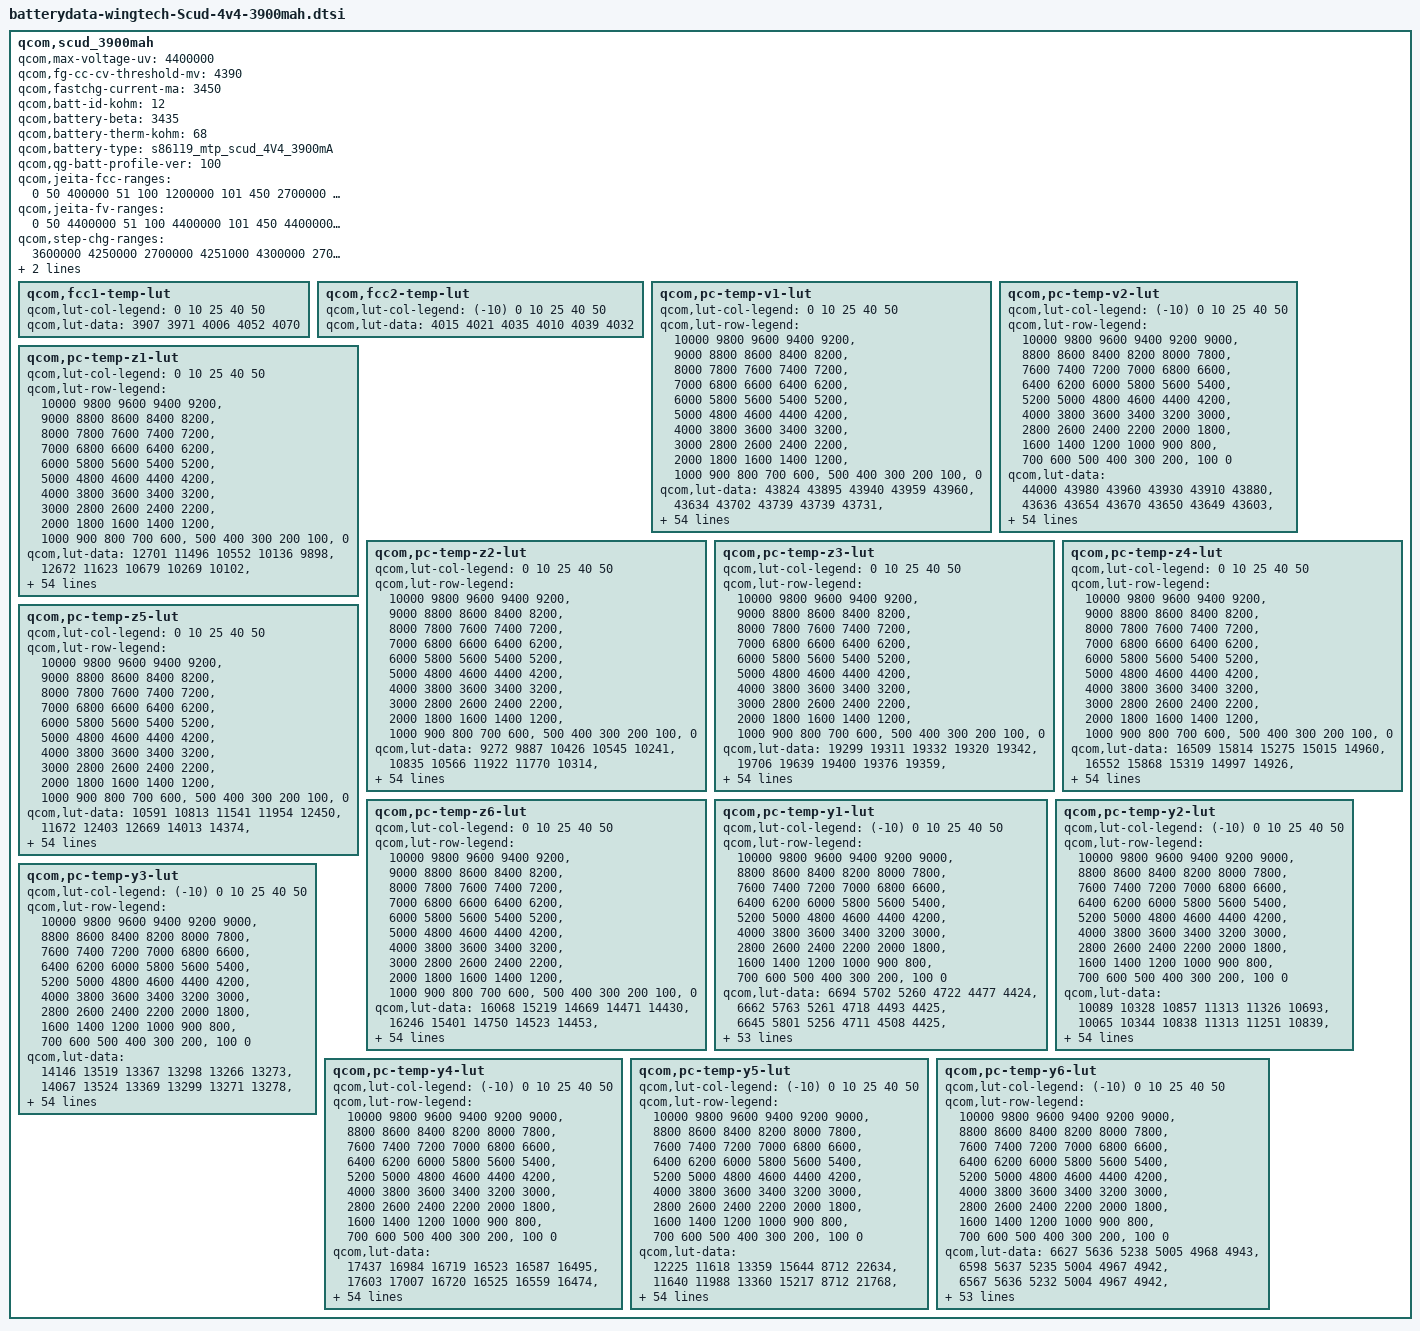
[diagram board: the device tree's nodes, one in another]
/* Copyright (c) 2018, The Linux Foundation. All rights reserved.
 *
 * This program is free software; you can redistribute it and/or modify
 * it under the terms of the GNU General Public License version 2 and
 * only version 2 as published by the Free Software Foundation.
 *
 * This program is distributed in the hope that it will be useful,
 * but WITHOUT ANY WARRANTY; without even the implied warranty of
 * MERCHANTABILITY or FITNESS FOR A PARTICULAR PURPOSE.  See the
 * GNU General Public License for more details.
 */

qcom,scud_3900mah {
	/* Scud_wConn_3900mAh_Fresh_averaged_MasterSlave_Feb7th2018 */
	qcom,max-voltage-uv = <4400000>;
	qcom,fg-cc-cv-threshold-mv = <4390>;
	qcom,fastchg-current-ma = <3450>;
	qcom,batt-id-kohm = <12>;
	qcom,battery-beta = <3435>;
	qcom,battery-therm-kohm = <68>;
	qcom,battery-type =
		"s86119_mtp_scud_4V4_3900mA";
	qcom,qg-batt-profile-ver = <100>;
	//+Bug 439935 gudi.wt,MODIFIY,20190628,S86119AA1 set follow to batt spec
	qcom,jeita-fcc-ranges = <0   50  400000
				51  100  1200000
				101  450 2700000
				451  600 1400000>;
	qcom,jeita-fv-ranges = <0   50  4400000
				51 100  4400000
				101 450 4400000
				451 600  4100000>;
	qcom,step-chg-ranges = <3600000  4250000  2700000
				4251000  4300000  2700000
				4301000  4400000  2700000>;

	/* COOL = 5 DegC, WARM = 45 DegC */
	qcom,jeita-soft-thresholds = <0x2E1E 0x123E>;
	/* COLD = 0 DegC, HOT = 55 DegC */
	qcom,jeita-hard-thresholds = <0x3480 0x0F3B>;
	//+Bug 439935 gudi.wt,MODIFIY,20190628,S86119AA1 set follow to batt spec
	qcom,fcc1-temp-lut {
		qcom,lut-col-legend = <0 10 25 40 50>;
		qcom,lut-data = <3907 3971 4006 4052 4070>;
	};

	qcom,fcc2-temp-lut {
		qcom,lut-col-legend = <(-10) 0 10 25 40 50>;
		qcom,lut-data = <4015 4021 4035 4010 4039 4032>;
	};

	qcom,pc-temp-v1-lut {
		qcom,lut-col-legend = <0 10 25 40 50>;
		qcom,lut-row-legend = <10000 9800 9600 9400 9200>,
			<9000 8800 8600 8400 8200>,
			<8000 7800 7600 7400 7200>,
			<7000 6800 6600 6400 6200>,
			<6000 5800 5600 5400 5200>,
			<5000 4800 4600 4400 4200>,
			<4000 3800 3600 3400 3200>,
			<3000 2800 2600 2400 2200>,
			<2000 1800 1600 1400 1200>,
			<1000 900 800 700 600>,
			<500 400 300 200 100>,
			<0>;
		qcom,lut-data = <43824 43895 43940 43959 43960>,
			<43634 43702 43739 43739 43731>,
			<43361 43461 43491 43522 43507>,
			<43106 43204 43258 43293 43285>,
			<42867 42961 43027 43060 43062>,
			<42631 42724 42792 42826 42834>,
			<42399 42491 42558 42593 42600>,
			<42171 42260 42324 42359 42365>,
			<41947 42034 42091 42128 42133>,
			<41728 41811 41862 41898 41903>,
			<41516 41589 41637 41670 41674>,
			<41321 41378 41418 41445 41449>,
			<41134 41183 41206 41227 41230>,
			<40931 40987 41003 41016 41018>,
			<40705 40771 40795 40809 40811>,
			<40477 40545 40585 40604 40606>,
			<40248 40335 40383 40405 40407>,
			<40026 40136 40191 40218 40220>,
			<39854 39957 40010 40040 40044>,
			<39720 39807 39846 39869 39872>,
			<39598 39672 39700 39716 39713>,
			<39473 39528 39536 39549 39545>,
			<39351 39382 39333 39309 39320>,
			<39232 39221 39120 39033 39048>,
			<39115 39017 38917 38851 38859>,
			<38999 38806 38720 38732 38742>,
			<38876 38659 38586 38631 38643>,
			<38755 38547 38500 38539 38545>,
			<38648 38463 38429 38456 38454>,
			<38551 38402 38364 38375 38365>,
			<38470 38353 38305 38298 38280>,
			<38405 38310 38248 38226 38203>,
			<38351 38273 38195 38162 38134>,
			<38307 38236 38143 38100 38070>,
			<38274 38199 38095 38041 38009>,
			<38239 38160 38049 37984 37950>,
			<38201 38120 38003 37930 37887>,
			<38159 38078 37960 37883 37823>,
			<38104 38021 37902 37824 37750>,
			<38030 37932 37811 37734 37660>,
			<37938 37822 37698 37621 37554>,
			<37811 37697 37578 37499 37433>,
			<37658 37553 37444 37361 37290>,
			<37487 37393 37286 37204 37137>,
			<37350 37253 37148 37063 37003>,
			<37253 37163 37067 36989 36925>,
			<37216 37137 37044 36968 36905>,
			<37190 37115 37030 36953 36891>,
			<37163 37098 37008 36932 36866>,
			<37107 37032 36926 36841 36757>,
			<36855 36755 36634 36540 36447>,
			<36406 36307 36180 36084 35990>,
			<35820 35712 35588 35491 35397>,
			<35020 34897 34775 34676 34583>,
			<33768 33616 33496 33401 33311>,
			<30000 30000 30000 30000 30000>;
	};

	qcom,pc-temp-v2-lut {
		qcom,lut-col-legend = <(-10) 0 10 25 40 50>;
		qcom,lut-row-legend = <10000 9800 9600 9400 9200 9000>,
			<8800 8600 8400 8200 8000 7800>,
			<7600 7400 7200 7000 6800 6600>,
			<6400 6200 6000 5800 5600 5400>,
			<5200 5000 4800 4600 4400 4200>,
			<4000 3800 3600 3400 3200 3000>,
			<2800 2600 2400 2200 2000 1800>,
			<1600 1400 1200 1000 900 800>,
			<700 600 500 400 300 200>,
			<100 0>;
		qcom,lut-data = <44000 43980 43960 43930 43910 43880>,
			<43636 43654 43670 43650 43649 43603>,
			<43299 43351 43397 43385 43395 43340>,
			<42990 43075 43138 43134 43149 43093>,
			<42705 42824 42895 42898 42909 42861>,
			<42446 42579 42657 42665 42672 42633>,
			<42224 42333 42422 42430 42435 42405>,
			<42006 42095 42191 42197 42203 42178>,
			<41733 41871 41962 41967 41981 41947>,
			<41426 41657 41735 41740 41766 41714>,
			<41217 41441 41512 41516 41546 41489>,
			<41108 41220 41293 41293 41321 41273>,
			<40990 41010 41083 41076 41099 41061>,
			<40758 40835 40898 40876 40890 40850>,
			<40433 40670 40718 40682 40686 40640>,
			<40115 40435 40503 40479 40482 40438>,
			<39784 40087 40245 40260 40277 40240>,
			<39512 39781 39994 40058 40085 40054>,
			<39337 39585 39766 39892 39917 39888>,
			<39192 39418 39551 39736 39751 39724>,
			<39034 39247 39357 39542 39560 39537>,
			<38870 39078 39178 39310 39350 39332>,
			<38714 38917 39011 39094 39145 39130>,
			<38556 38761 38850 38906 38939 38926>,
			<38416 38617 38703 38739 38758 38744>,
			<38309 38491 38573 38604 38623 38608>,
			<38222 38378 38455 38490 38512 38496>,
			<38147 38262 38346 38385 38406 38391>,
			<38080 38136 38246 38289 38307 38294>,
			<38018 38032 38152 38199 38216 38204>,
			<37954 37966 38063 38118 38139 38124>,
			<37891 37915 37981 38043 38067 38050>,
			<37830 37868 37907 37974 37994 37980>,
			<37769 37826 37838 37912 37921 37917>,
			<37710 37783 37782 37851 37845 37843>,
			<37653 37737 37743 37785 37763 37742>,
			<37597 37688 37706 37717 37677 37631>,
			<37536 37632 37663 37645 37583 37526>,
			<37470 37567 37614 37568 37485 37423>,
			<37406 37494 37550 37488 37397 37330>,
			<37346 37410 37462 37408 37325 37252>,
			<37285 37312 37358 37316 37231 37158>,
			<37216 37197 37235 37197 37106 37036>,
			<37139 37092 37086 37051 36970 36898>,
			<37046 36986 36960 36925 36852 36788>,
			<36934 36899 36901 36886 36823 36764>,
			<36865 36863 36880 36872 36808 36748>,
			<36795 36828 36856 36853 36788 36725>,
			<36684 36771 36816 36811 36741 36676>,
			<36534 36652 36706 36695 36609 36512>,
			<36274 36398 36404 36367 36243 36122>,
			<35851 35949 35893 35864 35723 35595>,
			<35236 35323 35219 35206 35044 34905>,
			<34338 34435 34268 34298 34098 33972>,
			<32794 33041 32942 33023 32903 32631>,
			<28257 29235 28091 28288 28281 28415>;
	};

	qcom,pc-temp-z1-lut {
		qcom,lut-col-legend = <0 10 25 40 50>;
		qcom,lut-row-legend = <10000 9800 9600 9400 9200>,
			<9000 8800 8600 8400 8200>,
			<8000 7800 7600 7400 7200>,
			<7000 6800 6600 6400 6200>,
			<6000 5800 5600 5400 5200>,
			<5000 4800 4600 4400 4200>,
			<4000 3800 3600 3400 3200>,
			<3000 2800 2600 2400 2200>,
			<2000 1800 1600 1400 1200>,
			<1000 900 800 700 600>,
			<500 400 300 200 100>,
			<0>;
		qcom,lut-data = <12701 11496 10552 10136 9898>,
			<12672 11623 10679 10269 10102>,
			<12762 11650 10684 10271 10108>,
			<12801 11686 10672 10270 10105>,
			<12815 11691 10661 10270 10102>,
			<12820 11689 10653 10266 10099>,
			<12807 11685 10645 10257 10097>,
			<12783 11665 10641 10252 10095>,
			<12773 11640 10637 10250 10093>,
			<12788 11630 10634 10249 10092>,
			<12801 11627 10631 10248 10091>,
			<12796 11620 10627 10247 10089>,
			<12788 11609 10625 10247 10089>,
			<12767 11594 10622 10245 10089>,
			<12693 11576 10619 10243 10089>,
			<12634 11555 10614 10241 10088>,
			<12628 11544 10612 10239 10088>,
			<12624 11545 10614 10238 10088>,
			<12625 11548 10617 10237 10089>,
			<12637 11552 10617 10237 10089>,
			<12646 11558 10615 10240 10089>,
			<12636 11559 10615 10242 10089>,
			<12611 11559 10619 10243 10089>,
			<12585 11561 10625 10244 10090>,
			<12550 11568 10628 10245 10091>,
			<12530 11578 10631 10247 10095>,
			<12561 11581 10634 10249 10098>,
			<12618 11582 10640 10252 10101>,
			<12627 11584 10647 10256 10104>,
			<12598 11588 10652 10258 10107>,
			<12574 11591 10657 10260 10108>,
			<12573 11588 10659 10263 10110>,
			<12577 11579 10661 10268 10114>,
			<12588 11575 10662 10274 10120>,
			<12609 11575 10667 10278 10123>,
			<12626 11576 10674 10281 10127>,
			<12636 11579 10680 10282 10129>,
			<12644 11583 10686 10283 10129>,
			<12651 11588 10692 10284 10130>,
			<12660 11600 10700 10287 10133>,
			<12665 11615 10707 10292 10137>,
			<12658 11632 10714 10295 10138>,
			<12642 11647 10722 10298 10139>,
			<12605 11636 10723 10301 10141>,
			<12581 11631 10728 10306 10144>,
			<12558 11619 10731 10310 10148>,
			<12626 11630 10736 10312 10149>,
			<12582 11588 10732 10315 10147>,
			<12565 11605 10731 10313 10149>,
			<12599 11606 10736 10317 10150>,
			<12619 11655 10740 10325 10155>,
			<12546 11672 10750 10325 10159>,
			<12580 11632 10768 10332 10169>,
			<12606 11680 10789 10343 10175>,
			<12606 11680 10789 10343 10175>,
			<12606 11680 10789 10343 10175>;
	};

	qcom,pc-temp-z2-lut {
		qcom,lut-col-legend = <0 10 25 40 50>;
		qcom,lut-row-legend = <10000 9800 9600 9400 9200>,
			<9000 8800 8600 8400 8200>,
			<8000 7800 7600 7400 7200>,
			<7000 6800 6600 6400 6200>,
			<6000 5800 5600 5400 5200>,
			<5000 4800 4600 4400 4200>,
			<4000 3800 3600 3400 3200>,
			<3000 2800 2600 2400 2200>,
			<2000 1800 1600 1400 1200>,
			<1000 900 800 700 600>,
			<500 400 300 200 100>,
			<0>;
		qcom,lut-data = <9272 9887 10426 10545 10241>,
			<10835 10566 11922 11770 10314>,
			<10312 10422 10557 11544 10575>,
			<10154 10226 10509 11106 10574>,
			<10144 10188 10469 10572 10504>,
			<10140 10180 10427 10500 10480>,
			<10151 10181 10399 10475 10474>,
			<10171 10188 10422 10468 10472>,
			<10176 10197 10481 10485 10477>,
			<10172 10204 10502 10508 10485>,
			<10169 10210 10494 10612 10489>,
			<10177 10216 10486 10793 10497>,
			<10192 10231 10486 10864 10484>,
			<10195 10245 10494 10895 10354>,
			<10190 10243 10523 10907 10245>,
			<10182 10229 10622 10873 10257>,
			<10164 10233 10685 10818 10287>,
			<10141 10276 10626 10735 10302>,
			<10142 10310 10536 10557 10308>,
			<10194 10306 10519 10493 10315>,
			<10244 10298 10532 10498 10332>,
			<10267 10296 10556 10514 10363>,
			<10284 10299 10627 10592 10487>,
			<10286 10304 10692 10720 10752>,
			<10274 10318 10686 10731 10819>,
			<10260 10336 10653 10609 10595>,
			<10246 10343 10629 10526 10415>,
			<10233 10347 10610 10560 10434>,
			<10231 10349 10599 10618 10487>,
			<10236 10350 10617 10657 10581>,
			<10244 10351 10656 10738 10784>,
			<10252 10354 10674 10769 10876>,
			<10261 10362 10689 10712 10742>,
			<10271 10369 10695 10655 10571>,
			<10280 10373 10673 10646 10505>,
			<10291 10377 10643 10644 10458>,
			<10303 10383 10639 10655 10474>,
			<10317 10392 10647 10710 10681>,
			<10340 10402 10659 10775 10835>,
			<10383 10415 10691 10848 10808>,
			<10427 10429 10728 10910 10765>,
			<10454 10443 10746 10896 10765>,
			<10488 10465 10763 10836 10795>,
			<10609 10520 10794 10841 10775>,
			<10542 10728 10887 10857 10689>,
			<10369 11076 11026 10767 10535>,
			<10368 11114 10971 10647 10510>,
			<10383 11244 11064 10617 10534>,
			<10300 11276 11008 10666 10575>,
			<10198 11123 11119 10780 10720>,
			<10328 11394 11357 10757 10510>,
			<10272 10919 11348 10793 10383>,
			<10040 10881 11178 10737 10259>,
			<9881 10675 11091 10551 10200>,
			<9881 10675 11091 10551 10200>,
			<9881 10675 11091 10551 10200>;
	};

	qcom,pc-temp-z3-lut {
		qcom,lut-col-legend = <0 10 25 40 50>;
		qcom,lut-row-legend = <10000 9800 9600 9400 9200>,
			<9000 8800 8600 8400 8200>,
			<8000 7800 7600 7400 7200>,
			<7000 6800 6600 6400 6200>,
			<6000 5800 5600 5400 5200>,
			<5000 4800 4600 4400 4200>,
			<4000 3800 3600 3400 3200>,
			<3000 2800 2600 2400 2200>,
			<2000 1800 1600 1400 1200>,
			<1000 900 800 700 600>,
			<500 400 300 200 100>,
			<0>;
		qcom,lut-data = <19299 19311 19332 19320 19342>,
			<19706 19639 19400 19376 19359>,
			<19945 19748 19549 19438 19425>,
			<20037 19820 19593 19478 19451>,
			<20073 19850 19605 19501 19460>,
			<20089 19868 19604 19501 19460>,
			<20068 19873 19601 19496 19454>,
			<20025 19861 19594 19490 19448>,
			<20010 19844 19581 19474 19439>,
			<20013 19835 19566 19459 19430>,
			<20014 19826 19547 19460 19426>,
			<19999 19815 19531 19467 19420>,
			<19978 19798 19520 19466 19411>,
			<19975 19783 19511 19460 19388>,
			<19997 19784 19509 19453 19372>,
			<20029 19791 19520 19443 19371>,
			<20078 19786 19530 19430 19372>,
			<20132 19740 19531 19416 19370>,
			<20133 19702 19532 19396 19363>,
			<20057 19699 19523 19386 19358>,
			<19996 19699 19489 19380 19356>,
			<19989 19703 19472 19377 19353>,
			<19991 19714 19489 19390 19360>,
			<19998 19728 19509 19418 19378>,
			<20012 19752 19512 19422 19383>,
			<20030 19778 19510 19404 19364>,
			<20055 19781 19504 19387 19345>,
			<20082 19776 19493 19375 19339>,
			<20088 19770 19480 19367 19335>,
			<20084 19763 19469 19369 19341>,
			<20079 19754 19459 19382 19370>,
			<20070 19742 19459 19393 19387>,
			<20057 19728 19468 19406 19389>,
			<20042 19718 19477 19415 19388>,
			<20013 19713 19482 19414 19382>,
			<19980 19708 19486 19410 19370>,
			<19951 19704 19486 19405 19367>,
			<19921 19700 19482 19399 19370>,
			<19888 19696 19477 19394 19372>,
			<19850 19689 19471 19390 19367>,
			<19814 19680 19464 19387 19360>,
			<19787 19671 19460 19385 19361>,
			<19757 19656 19456 19385 19369>,
			<19717 19626 19450 19384 19366>,
			<19518 19549 19430 19381 19353>,
			<19348 19454 19397 19352 19337>,
			<19345 19438 19395 19348 19333>,
			<19339 19409 19377 19344 19328>,
			<19332 19329 19375 19332 19320>,
			<19327 19366 19349 19324 19319>,
			<19340 19383 19324 19319 19328>,
			<19348 19338 19321 19315 19331>,
			<19347 19338 19315 19321 19338>,
			<19357 19333 19305 19322 19339>,
			<19357 19333 19305 19322 19339>,
			<19357 19333 19305 19322 19339>;
	};

	qcom,pc-temp-z4-lut {
		qcom,lut-col-legend = <0 10 25 40 50>;
		qcom,lut-row-legend = <10000 9800 9600 9400 9200>,
			<9000 8800 8600 8400 8200>,
			<8000 7800 7600 7400 7200>,
			<7000 6800 6600 6400 6200>,
			<6000 5800 5600 5400 5200>,
			<5000 4800 4600 4400 4200>,
			<4000 3800 3600 3400 3200>,
			<3000 2800 2600 2400 2200>,
			<2000 1800 1600 1400 1200>,
			<1000 900 800 700 600>,
			<500 400 300 200 100>,
			<0>;
		qcom,lut-data = <16509 15814 15275 15015 14960>,
			<16552 15868 15319 14997 14926>,
			<16740 15830 15397 15083 14955>,
			<16771 15761 15270 15038 14956>,
			<16575 15667 15166 14964 14898>,
			<16338 15505 15106 14910 14854>,
			<16172 15373 15053 14862 14816>,
			<16023 15291 14988 14839 14796>,
			<15899 15223 14923 14830 14789>,
			<15795 15162 14897 14822 14784>,
			<15706 15108 14889 14801 14777>,
			<15630 15057 14882 14770 14766>,
			<15563 15005 14869 14751 14763>,
			<15498 14961 14851 14737 14767>,
			<15430 14925 14834 14728 14771>,
			<15366 14894 14804 14725 14762>,
			<15303 14890 14774 14723 14743>,
			<15248 14923 14749 14722 14729>,
			<15236 14951 14726 14726 14718>,
			<15259 14930 14720 14727 14712>,
			<15273 14881 14730 14725 14710>,
			<15231 14846 14746 14725 14709>,
			<15146 14818 14765 14756 14734>,
			<15080 14805 14787 14825 14807>,
			<15024 14829 14827 14859 14847>,
			<14981 14871 14886 14877 14865>,
			<14948 14892 14904 14884 14873>,
			<14920 14907 14901 14881 14869>,
			<14911 14913 14896 14873 14859>,
			<14910 14906 14889 14857 14837>,
			<14909 14893 14877 14825 14787>,
			<14907 14882 14859 14793 14748>,
			<14904 14870 14829 14757 14724>,
			<14901 14857 14800 14731 14710>,
			<14899 14843 14776 14725 14710>,
			<14898 14829 14756 14722 14712>,
			<14901 14817 14748 14722 14715>,
			<14905 14804 14743 14724 14717>,
			<14909 14800 14742 14729 14721>,
			<14917 14800 14758 14742 14732>,
			<14922 14800 14776 14758 14747>,
			<14922 14798 14774 14758 14746>,
			<14922 14793 14766 14750 14733>,
			<14903 14794 14762 14746 14735>,
			<14957 14789 14752 14738 14738>,
			<15029 14789 14720 14715 14709>,
			<15031 14799 14709 14706 14698>,
			<15029 14823 14709 14686 14678>,
			<15031 14903 14697 14681 14664>,
			<15023 14857 14732 14699 14679>,
			<15021 14855 14793 14741 14703>,
			<15028 14920 14807 14752 14706>,
			<15045 14927 14820 14747 14701>,
			<15051 14943 14835 14749 14701>,
			<15051 14943 14835 14749 14701>,
			<15051 14943 14835 14749 14701>;
	};

	qcom,pc-temp-z5-lut {
		qcom,lut-col-legend = <0 10 25 40 50>;
		qcom,lut-row-legend = <10000 9800 9600 9400 9200>,
			<9000 8800 8600 8400 8200>,
			<8000 7800 7600 7400 7200>,
			<7000 6800 6600 6400 6200>,
			<6000 5800 5600 5400 5200>,
			<5000 4800 4600 4400 4200>,
			<4000 3800 3600 3400 3200>,
			<3000 2800 2600 2400 2200>,
			<2000 1800 1600 1400 1200>,
			<1000 900 800 700 600>,
			<500 400 300 200 100>,
			<0>;
		qcom,lut-data = <10591 10813 11541 11954 12450>,
			<11672 12403 12669 14013 14374>,
			<12465 13253 14746 14821 16533>,
			<12835 13841 15318 15727 16919>,
			<13006 14292 15539 16708 17258>,
			<13133 14664 15582 17319 17707>,
			<13257 14884 15619 17854 18508>,
			<13374 15023 16106 17993 19029>,
			<13512 15174 17031 17691 18821>,
			<13696 15401 17271 17422 18463>,
			<13857 15810 16987 18278 18495>,
			<13912 16290 16762 20191 18571>,
			<13917 16856 16912 21564 18285>,
			<14017 17581 17181 22720 16967>,
			<14337 18999 17476 23205 15951>,
			<14819 20986 19439 22738 16369>,
			<15888 21302 21654 21904 17287>,
			<17249 18700 23830 20839 17814>,
			<17369 16549 25957 19143 18301>,
			<16032 16933 26120 18758 18643>,
			<15034 18157 23843 19196 19102>,
			<15387 19892 23488 19984 20002>,
			<16322 23137 32117 25736 23536>,
			<17503 27594 41970 36239 30940>,
			<19296 36618 43062 37572 32778>,
			<21651 46677 40353 29543 25823>,
			<25653 47664 36928 22563 19130>,
			<30521 43843 31739 19505 17022>,
			<33033 39772 26828 17542 15743>,
			<34691 36390 23604 17232 15934>,
			<35761 33169 21154 17605 17830>,
			<35442 30428 20700 18335 19786>,
			<34063 27892 21363 20620 21851>,
			<32611 26868 22314 23545 23590>,
			<29713 26742 24216 26229 24168>,
			<26874 26674 26668 28718 24538>,
			<24984 26932 28084 29179 25208>,
			<23328 27728 29139 28514 27163>,
			<21956 28065 29473 27482 28479>,
			<20574 28669 28087 25117 25377>,
			<19667 29143 26060 22279 20440>,
			<19337 28591 24792 21270 19931>,
			<19127 27368 23840 20799 20809>,
			<19413 25148 22870 20398 19907>,
			<16442 22199 22233 20178 18005>,
			<12973 18593 21230 18713 17447>,
			<12872 16843 20911 18148 17294>,
			<12719 15247 18407 18384 17682>,
			<12590 12790 18434 17667 18456>,
			<12618 14171 16119 15930 17259>,
			<12913 14437 13665 13726 14818>,
			<12877 12937 13151 13132 14416>,
			<12662 12805 12759 13181 14552>,
			<12541 12512 12349 13008 14368>,
			<12541 12512 12349 13008 14368>,
			<12541 12512 12349 13008 14368>;
	};

	qcom,pc-temp-z6-lut {
		qcom,lut-col-legend = <0 10 25 40 50>;
		qcom,lut-row-legend = <10000 9800 9600 9400 9200>,
			<9000 8800 8600 8400 8200>,
			<8000 7800 7600 7400 7200>,
			<7000 6800 6600 6400 6200>,
			<6000 5800 5600 5400 5200>,
			<5000 4800 4600 4400 4200>,
			<4000 3800 3600 3400 3200>,
			<3000 2800 2600 2400 2200>,
			<2000 1800 1600 1400 1200>,
			<1000 900 800 700 600>,
			<500 400 300 200 100>,
			<0>;
		qcom,lut-data = <16068 15219 14669 14471 14430>,
			<16246 15401 14750 14523 14453>,
			<16391 15412 14840 14592 14503>,
			<16416 15417 14813 14585 14514>,
			<16340 15400 14784 14572 14498>,
			<16237 15325 14758 14556 14481>,
			<16133 15256 14730 14531 14463>,
			<16021 15207 14697 14513 14449>,
			<15945 15163 14662 14500 14441>,
			<15895 15126 14640 14489 14434>,
			<15851 15093 14627 14479 14427>,
			<15800 15061 14616 14471 14420>,
			<15750 15027 14604 14462 14412>,
			<15709 14997 14591 14453 14403>,
			<15670 14977 14582 14444 14395>,
			<15645 14962 14574 14436 14388>,
			<15641 14951 14566 14428 14381>,
			<15643 14944 14557 14419 14374>,
			<15635 14936 14546 14410 14365>,
			<15614 14921 14536 14404 14359>,
			<15587 14904 14525 14400 14356>,
			<15552 14897 14521 14398 14354>,
			<15511 14894 14537 14420 14370>,
			<15486 14893 14560 14465 14413>,
			<15468 14915 14580 14476 14428>,
			<15460 14951 14604 14475 14425>,
			<15466 14960 14610 14473 14421>,
			<15476 14962 14604 14467 14417>,
			<15477 14962 14595 14459 14411>,
			<15468 14958 14587 14453 14405>,
			<15460 14950 14578 14446 14399>,
			<15461 14940 14570 14439 14393>,
			<15463 14926 14562 14432 14386>,
			<15457 14915 14555 14426 14379>,
			<15441 14908 14549 14422 14375>,
			<15426 14902 14543 14419 14371>,
			<15415 14897 14540 14417 14370>,
			<15405 14892 14536 14415 14372>,
			<15392 14890 14535 14414 14374>,
			<15373 14891 14540 14418 14377>,
			<15359 14892 14546 14423 14379>,
			<15355 14890 14545 14423 14379>,
			<15349 14886 14540 14419 14378>,
			<15319 14870 14535 14418 14377>,
			<15231 14827 14522 14413 14373>,
			<15168 14787 14493 14389 14352>,
			<15182 14786 14487 14382 14346>,
			<15173 14775 14478 14373 14333>,
			<15166 14769 14471 14363 14323>,
			<15175 14776 14474 14368 14328>,
			<15191 14788 14489 14385 14346>,
			<15191 14804 14495 14389 14351>,
			<15210 14805 14502 14392 14355>,
			<15249 14826 14509 14396 14358>,
			<15249 14826 14509 14396 14358>,
			<15249 14826 14509 14396 14358>;
	};

	qcom,pc-temp-y1-lut {
		qcom,lut-col-legend = <(-10) 0 10 25 40 50>;
		qcom,lut-row-legend = <10000 9800 9600 9400 9200 9000>,
			<8800 8600 8400 8200 8000 7800>,
			<7600 7400 7200 7000 6800 6600>,
			<6400 6200 6000 5800 5600 5400>,
			<5200 5000 4800 4600 4400 4200>,
			<4000 3800 3600 3400 3200 3000>,
			<2800 2600 2400 2200 2000 1800>,
			<1600 1400 1200 1000 900 800>,
			<700 600 500 400 300 200>,
			<100 0>;
		qcom,lut-data = <6694 5702 5260 4722 4477 4424>,
			<6662 5763 5261 4718 4493 4425>,
			<6645 5801 5256 4711 4508 4425>,
			<6640 5822 5250 4703 4522 4424>,
			<6640 5830 5245 4696 4535 4422>,
			<6641 5831 5243 4692 4544 4419>,
			<6653 5802 5242 4688 4554 4401>,
			<6666 5770 5241 4685 4560 4383>,
			<6661 5774 5240 4683 4554 4388>,
			<6645 5790 5239 4681 4541 4406>,
			<6639 5795 5237 4678 4537 4409>,
			<6631 5789 5230 4674 4538 4390>,
			<6628 5783 5221 4671 4539 4373>,
			<6643 5784 5209 4669 4514 4369>,
			<6665 5787 5197 4669 4473 4367>,
			<6676 5788 5195 4668 4466 4369>,
			<6688 5789 5199 4667 4473 4377>,
			<6695 5791 5201 4666 4476 4382>,
			<6669 5801 5202 4667 4472 4381>,
			<6631 5815 5203 4669 4467 4379>,
			<6632 5819 5203 4670 4481 4376>,
			<6653 5824 5202 4671 4523 4368>,
			<6664 5827 5203 4673 4537 4366>,
			<6663 5819 5207 4676 4532 4375>,
			<6661 5810 5211 4680 4522 4383>,
			<6657 5811 5211 4682 4498 4380>,
			<6648 5811 5207 4684 4467 4372>,
			<6645 5810 5207 4687 4463 4371>,
			<6653 5805 5210 4691 4475 4373>,
			<6657 5800 5213 4696 4492 4376>,
			<6635 5796 5218 4702 4521 4377>,
			<6599 5788 5225 4709 4548 4378>,
			<6592 5781 5225 4711 4538 4380>,
			<6607 5774 5223 4711 4492 4383>,
			<6619 5771 5226 4712 4474 4386>,
			<6632 5788 5241 4717 4477 4390>,
			<6647 5808 5255 4726 4480 4394>,
			<6647 5803 5251 4732 4483 4394>,
			<6639 5780 5241 4737 4487 4394>,
			<6628 5772 5239 4740 4489 4395>,
			<6611 5778 5257 4739 4491 4398>,
			<6601 5781 5259 4740 4491 4400>,
			<6610 5779 5244 4746 4492 4399>,
			<6579 5812 5267 4747 4499 4401>,
			<6623 5824 5277 4754 4499 4404>,
			<6644 5812 5272 4754 4506 4404>,
			<6629 5795 5272 4758 4504 4406>,
			<6637 5787 5257 4762 4504 4402>,
			<6616 5768 5280 4765 4499 4405>,
			<6604 5788 5276 4765 4502 4402>,
			<6616 5825 5281 4767 4500 4405>,
			<6581 5801 5291 4773 4508 4409>,
			<6693 5792 5305 4781 4514 4415>,
			<6733 5855 5300 4796 4525 4421>,
			<6733 5855 5300 4796 4525 4421>,
			<6733 5855 5300 4796 4525 4421>;
	};

	qcom,pc-temp-y2-lut {
		qcom,lut-col-legend = <(-10) 0 10 25 40 50>;
		qcom,lut-row-legend = <10000 9800 9600 9400 9200 9000>,
			<8800 8600 8400 8200 8000 7800>,
			<7600 7400 7200 7000 6800 6600>,
			<6400 6200 6000 5800 5600 5400>,
			<5200 5000 4800 4600 4400 4200>,
			<4000 3800 3600 3400 3200 3000>,
			<2800 2600 2400 2200 2000 1800>,
			<1600 1400 1200 1000 900 800>,
			<700 600 500 400 300 200>,
			<100 0>;
		qcom,lut-data = <10089 10328 10857 11313 11326 10693>,
			<10065 10344 10838 11313 11251 10839>,
			<10058 10360 10816 11306 11175 10946>,
			<10066 10376 10796 11294 11108 11017>,
			<10084 10392 10780 11278 11062 11053>,
			<10108 10408 10773 11258 11049 11055>,
			<10139 10427 10771 11228 11068 11006>,
			<10184 10442 10771 11201 11089 10946>,
			<10295 10434 10780 11195 11039 10917>,
			<10483 10411 10797 11205 10912 10897>,
			<10542 10408 10804 11222 10886 10897>,
			<10485 10473 10804 11266 11012 10957>,
			<10435 10558 10804 11301 11131 11031>,
			<10491 10637 10810 11295 11173 11087>,
			<10605 10709 10823 11275 11207 11139>,
			<10556 10721 10851 11281 11223 11183>,
			<10052 10711 10919 11351 11245 11219>,
			<9703 10705 10957 11406 11274 11263>,
			<9686 10741 10954 11414 11334 11347>,
			<9677 10806 10950 11414 11389 11426>,
			<9673 10858 10961 11397 11388 11444>,
			<9671 10908 10997 11347 11365 11451>,
			<9669 10961 11036 11321 11329 11442>,
			<9668 11037 11079 11330 11230 11251>,
			<9666 11092 11121 11348 11155 11073>,
			<9665 11080 11156 11376 11224 11107>,
			<9663 11044 11188 11418 11364 11199>,
			<9662 11043 11210 11449 11409 11237>,
			<9661 11136 11229 11473 11410 11247>,
			<9661 11211 11237 11492 11409 11258>,
			<9660 11184 11225 11500 11385 11319>,
			<9660 11120 11209 11502 11357 11409>,
			<9659 11066 11210 11501 11399 11459>,
			<9658 11018 11227 11498 11508 11539>,
			<9658 10951 11235 11494 11548 11572>,
			<9658 10666 11211 11487 11440 11557>,
			<9657 10343 11175 11478 11323 11527>,
			<9657 10179 11129 11474 11302 11452>,
			<9657 9845 11067 11472 11303 11302>,
			<9657 9683 11035 11468 11289 11189>,
			<9656 9674 11019 11448 11180 11100>,
			<9656 9669 10988 11433 11143 11100>,
			<9656 9666 10926 11442 11153 11185>,
			<9656 9663 10892 11345 11310 11094>,
			<9656 9665 10864 11360 11051 11162>,
			<9656 9662 10815 11312 11129 11028>,
			<9656 9660 10755 11310 11249 10904>,
			<9655 9659 10692 11221 11112 10796>,
			<9655 9658 10637 11180 11032 10934>,
			<9655 9657 10441 11166 11118 10792>,
			<9654 9656 10611 11218 11017 10820>,
			<9654 9655 10500 11152 10861 10684>,
			<9653 9654 10384 10973 10834 10665>,
			<9651 9653 10078 10883 10844 10683>,
			<9651 9653 10078 10883 10844 10683>,
			<9651 9653 10078 10883 10844 10683>;
	};

	qcom,pc-temp-y3-lut {
		qcom,lut-col-legend = <(-10) 0 10 25 40 50>;
		qcom,lut-row-legend = <10000 9800 9600 9400 9200 9000>,
			<8800 8600 8400 8200 8000 7800>,
			<7600 7400 7200 7000 6800 6600>,
			<6400 6200 6000 5800 5600 5400>,
			<5200 5000 4800 4600 4400 4200>,
			<4000 3800 3600 3400 3200 3000>,
			<2800 2600 2400 2200 2000 1800>,
			<1600 1400 1200 1000 900 800>,
			<700 600 500 400 300 200>,
			<100 0>;
		qcom,lut-data = <14146 13519 13367 13298 13266 13273>,
			<14067 13524 13369 13299 13271 13278>,
			<14002 13531 13371 13299 13281 13283>,
			<13953 13537 13374 13299 13291 13287>,
			<13923 13541 13377 13299 13300 13289>,
			<13915 13543 13378 13299 13304 13290>,
			<13937 13541 13381 13300 13305 13290>,
			<13963 13540 13384 13300 13306 13288>,
			<13928 13542 13383 13301 13306 13288>,
			<13813 13551 13381 13304 13305 13287>,
			<13726 13559 13381 13305 13305 13288>,
			<13662 13567 13383 13305 13306 13291>,
			<13626 13571 13388 13306 13308 13294>,
			<13649 13548 13396 13309 13307 13293>,
			<13694 13503 13405 13312 13307 13293>,
			<13689 13494 13406 13313 13308 13293>,
			<13581 13496 13402 13311 13314 13292>,
			<13506 13497 13397 13310 13317 13292>,
			<13507 13487 13391 13314 13307 13293>,
			<13512 13469 13383 13320 13295 13294>,
			<13518 13456 13375 13320 13295 13294>,
			<13525 13446 13366 13316 13296 13291>,
			<13527 13435 13360 13311 13295 13288>,
			<13515 13418 13354 13304 13293 13283>,
			<13501 13404 13349 13299 13291 13278>,
			<13505 13404 13346 13298 13289 13278>,
			<13523 13406 13344 13299 13286 13279>,
			<13543 13403 13343 13299 13285 13279>,
			<13566 13371 13341 13299 13285 13277>,
			<13592 13346 13340 13299 13286 13275>,
			<13619 13348 13341 13300 13286 13276>,
			<13648 13354 13343 13301 13286 13278>,
			<13684 13359 13342 13302 13287 13279>,
			<13729 13372 13336 13303 13288 13281>,
			<13777 13384 13333 13304 13288 13281>,
			<13826 13390 13339 13305 13287 13281>,
			<13876 13396 13346 13305 13286 13280>,
			<13921 13406 13350 13304 13283 13279>,
			<13965 13421 13356 13300 13279 13276>,
			<14015 13436 13357 13298 13279 13276>,
			<14083 13453 13356 13298 13282 13277>,
			<14145 13471 13354 13298 13283 13278>,
			<14193 13490 13350 13298 13281 13280>,
			<14227 13535 13344 13293 13281 13279>,
			<14093 13489 13328 13293 13283 13277>,
			<14209 13567 13338 13296 13287 13286>,
			<14275 13636 13346 13298 13289 13286>,
			<14374 13693 13355 13304 13294 13290>,
			<14431 13754 13366 13308 13296 13292>,
			<14558 13829 13375 13313 13299 13290>,
			<14656 13941 13380 13300 13289 13287>,
			<14769 14068 13383 13303 13290 13289>,
			<15107 14270 13401 13318 13294 13290>,
			<15838 14524 13437 13333 13305 13302>,
			<15838 14524 13437 13333 13305 13302>,
			<15838 14524 13437 13333 13305 13302>;
	};

	qcom,pc-temp-y4-lut {
		qcom,lut-col-legend = <(-10) 0 10 25 40 50>;
		qcom,lut-row-legend = <10000 9800 9600 9400 9200 9000>,
			<8800 8600 8400 8200 8000 7800>,
			<7600 7400 7200 7000 6800 6600>,
			<6400 6200 6000 5800 5600 5400>,
			<5200 5000 4800 4600 4400 4200>,
			<4000 3800 3600 3400 3200 3000>,
			<2800 2600 2400 2200 2000 1800>,
			<1600 1400 1200 1000 900 800>,
			<700 600 500 400 300 200>,
			<100 0>;
		qcom,lut-data = <17437 16984 16719 16523 16587 16495>,
			<17603 17007 16720 16525 16559 16474>,
			<17701 17028 16721 16528 16524 16461>,
			<17750 17046 16723 16532 16489 16454>,
			<17767 17058 16725 16536 16465 16451>,
			<17766 17061 16726 16540 16458 16451>,
			<17650 17055 16725 16548 16462 16464>,
			<17519 17048 16726 16557 16470 16481>,
			<17528 17047 16734 16565 16486 16487>,
			<17601 17048 16750 16575 16512 16491>,
			<17702 17047 16760 16584 16530 16495>,
			<17910 17039 16766 16597 16545 16500>,
			<18063 17032 16772 16612 16553 16505>,
			<17861 17122 16799 16626 16554 16510>,
			<17453 17293 16836 16642 16557 16517>,
			<17363 17291 16841 16661 16562 16525>,
			<17422 17048 16830 16686 16566 16538>,
			<17461 16889 16812 16706 16573 16553>,
			<17441 16885 16759 16719 16622 16580>,
			<17397 16883 16698 16728 16676 16604>,
			<17341 16874 16671 16713 16672 16602>,
			<17260 16855 16655 16642 16643 16585>,
			<17192 16839 16644 16582 16605 16563>,
			<17139 16829 16634 16547 16541 16523>,
			<17103 16818 16629 16525 16496 16491>,
			<17096 16789 16629 16524 16497 16487>,
			<17093 16744 16631 16527 16503 16485>,
			<17091 16732 16632 16530 16510 16487>,
			<17086 16746 16636 16538 16523 16499>,
			<17082 16759 16638 16549 16536 16514>,
			<17083 16763 16630 16560 16549 16526>,
			<17087 16765 16618 16572 16561 16537>,
			<17091 16764 16618 16584 16565 16549>,
			<17096 16758 16625 16597 16568 16561>,
			<17100 16758 16632 16604 16568 16565>,
			<17103 16783 16642 16597 16557 16545>,
			<17107 16818 16653 16583 16540 16516>,
			<17120 16847 16664 16570 16524 16502>,
			<17158 16890 16676 16556 16507 16491>,
			<17193 16908 16681 16550 16504 16489>,
			<17218 16904 16679 16554 16511 16496>,
			<17237 16896 16679 16558 16513 16497>,
			<17252 16884 16680 16557 16512 16489>,
			<17230 16864 16660 16552 16508 16484>,
			<17073 16838 16646 16515 16475 16463>,
			<17087 16857 16658 16539 16498 16478>,
			<17113 16871 16676 16561 16511 16496>,
			<17136 16900 16709 16585 16526 16515>,
			<17159 16934 16748 16608 16549 16537>,
			<17159 16967 16783 16604 16540 16527>,
			<17139 16969 16739 16577 16508 16482>,
			<17131 16959 16730 16567 16510 16485>,
			<17261 16971 16753 16565 16518 16497>,
			<17692 17038 16817 16592 16551 16546>,
			<17692 17038 16817 16592 16551 16546>,
			<17692 17038 16817 16592 16551 16546>;
	};

	qcom,pc-temp-y5-lut {
		qcom,lut-col-legend = <(-10) 0 10 25 40 50>;
		qcom,lut-row-legend = <10000 9800 9600 9400 9200 9000>,
			<8800 8600 8400 8200 8000 7800>,
			<7600 7400 7200 7000 6800 6600>,
			<6400 6200 6000 5800 5600 5400>,
			<5200 5000 4800 4600 4400 4200>,
			<4000 3800 3600 3400 3200 3000>,
			<2800 2600 2400 2200 2000 1800>,
			<1600 1400 1200 1000 900 800>,
			<700 600 500 400 300 200>,
			<100 0>;
		qcom,lut-data = <12225 11618 13359 15644 8712 22634>,
			<11640 11988 13360 15217 8712 21768>,
			<11391 12376 13437 14772 12213 20814>,
			<11404 12744 13542 14351 17633 19870>,
			<11605 13055 13632 13996 21056 19032>,
			<11943 13273 13667 13747 21890 18400>,
			<13139 13394 13824 13482 19571 17955>,
			<14320 13523 13965 13226 17122 17469>,
			<13835 13935 13807 13087 17302 16498>,
			<12240 14655 13498 13015 18197 15147>,
			<11701 14865 13428 12995 18239 14708>,
			<12205 14593 13705 12856 16147 15367>,
			<13136 14360 14073 12723 14468 15835>,
			<15734 14567 14346 12727 14098 15222>,
			<19562 15151 14661 12761 13647 14248>,
			<19690 15986 15504 12819 14009 13736>,
			<14778 17484 17663 12949 16056 13461>,
			<11493 18303 18796 13215 17124 13372>,
			<11695 17416 18683 14583 15341 13311>,
			<12057 16126 18446 16740 13253 13238>,
			<12297 15864 17981 18121 13784 13817>,
			<12496 15946 17088 19280 16021 15639>,
			<12560 15963 16409 19684 17625 16342>,
			<12212 15673 15833 18150 19054 16026>,
			<11758 15380 15424 16243 19920 15672>,
			<11570 16117 15298 15901 18921 15545>,
			<11443 17963 15224 15869 16864 15430>,
			<11417 18203 15218 15886 15881 15132>,
			<11492 15019 15288 15902 15345 14209>,
			<11556 12441 15413 15969 15142 13619>,
			<11522 12463 16028 16162 16051 13802>,
			<11446 12670 16818 16481 17273 14203>,
			<11412 12932 16604 16867 17310 14659>,
			<11390 13692 15327 17462 16831 15271>,
			<11380 14208 14737 17966 16744 15840>,
			<11443 14050 15327 18352 16941 16420>,
			<11536 13801 15980 18700 17073 16812>,
			<11495 13593 16250 18373 16403 16511>,
			<11278 12867 16711 16785 14890 15582>,
			<11174 12516 16674 15761 14514 15007>,
			<11276 12487 15971 15255 14808 14680>,
			<11413 12389 15301 14965 14614 14663>,
			<11549 12017 14731 14678 13742 14937>,
			<11759 12125 13983 13879 14230 15298>,
			<12004 11858 12780 14458 15978 15257>,
			<12054 11843 12993 13739 14367 15729>,
			<11922 12016 13209 13317 14007 14620>,
			<12060 12259 13248 13338 14395 14920>,
			<11937 12434 13560 13268 14202 15124>,
			<12433 12502 13744 13926 15120 14552>,
			<12515 12604 14294 12944 13797 15402>,
			<12209 12329 13896 13332 13816 15229>,
			<11549 12352 13978 14974 14484 15661>,
			<10909 12100 13928 18103 18875 20461>,
			<10909 12100 13928 18103 18875 20461>,
			<10909 12100 13928 18103 18875 20461>;
	};

	qcom,pc-temp-y6-lut {
		qcom,lut-col-legend = <(-10) 0 10 25 40 50>;
		qcom,lut-row-legend = <10000 9800 9600 9400 9200 9000>,
			<8800 8600 8400 8200 8000 7800>,
			<7600 7400 7200 7000 6800 6600>,
			<6400 6200 6000 5800 5600 5400>,
			<5200 5000 4800 4600 4400 4200>,
			<4000 3800 3600 3400 3200 3000>,
			<2800 2600 2400 2200 2000 1800>,
			<1600 1400 1200 1000 900 800>,
			<700 600 500 400 300 200>,
			<100 0>;
		qcom,lut-data = <6627 5636 5238 5005 4968 4943>,
			<6598 5637 5235 5004 4967 4942>,
			<6567 5636 5232 5004 4967 4942>,
			<6536 5634 5230 5005 4967 4942>,
			<6509 5631 5227 5005 4967 4943>,
			<6489 5628 5225 5007 4968 4944>,
			<6476 5618 5223 5008 4971 4945>,
			<6462 5609 5221 5011 4976 4947>,
			<6435 5608 5221 5013 4980 4949>,
			<6393 5612 5223 5017 4985 4953>,
			<6381 5613 5224 5021 4989 4955>,
			<6400 5613 5225 5025 4994 4956>,
			<6417 5613 5226 5029 4998 4958>,
			<6391 5621 5235 5035 4996 4959>,
			<6327 5637 5249 5041 4992 4961>,
			<6270 5631 5251 5047 4993 4963>,
			<6210 5573 5246 5052 4999 4967>,
			<6176 5526 5237 5057 5004 4972>,
			<6179 5512 5216 5064 5011 4980>,
			<6188 5504 5192 5070 5017 4987>,
			<6189 5498 5179 5066 5016 4986>,
			<6189 5494 5170 5042 5011 4978>,
			<6186 5488 5163 5022 5004 4969>,
			<6169 5477 5157 5007 4984 4954>,
			<6153 5467 5153 4997 4966 4943>,
			<6161 5467 5152 4997 4962 4940>,
			<6192 5468 5152 4998 4959 4939>,
			<6221 5470 5153 5000 4959 4940>,
			<6244 5473 5156 5003 4964 4942>,
			<6267 5478 5159 5007 4971 4946>,
			<6291 5488 5159 5011 4978 4950>,
			<6317 5506 5160 5016 4984 4954>,
			<6349 5528 5162 5021 4985 4959>,
			<6390 5558 5166 5026 4982 4964>,
			<6433 5591 5172 5029 4979 4965>,
			<6473 5626 5183 5028 4975 4959>,
			<6512 5663 5197 5025 4970 4951>,
			<6551 5698 5209 5021 4964 4945>,
			<6591 5731 5221 5015 4957 4941>,
			<6637 5768 5231 5013 4956 4940>,
			<6694 5811 5240 5014 4961 4943>,
			<6745 5851 5248 5016 4962 4944>,
			<6786 5882 5257 5017 4961 4944>,
			<6806 5943 5261 5013 4960 4942>,
			<6682 5886 5241 5002 4952 4935>,
			<6773 5979 5272 5012 4962 4946>,
			<6832 6051 5293 5021 4968 4952>,
			<6920 6116 5322 5032 4976 4960>,
			<6967 6174 5361 5042 4984 4968>,
			<7067 6246 5394 5045 4982 4963>,
			<7141 6349 5409 5029 4967 4949>,
			<7233 6457 5442 5030 4968 4951>,
			<7593 6619 5524 5042 4975 4957>,
			<8377 6859 5623 5063 4995 4980>,
			<8377 6859 5623 5063 4995 4980>,
			<8377 6859 5623 5063 4995 4980>;
	};

};
